# STM32U5A9 register map
File version: 1.0
CPU: CM33 r0p1, little endian, MPU, FPU, 4 interrupt priority bits
Registers are 32-bit, read-write, reset 0x0 unless marked. A register's access mark holds for its fields unless they carry their own. Offsets are from the block's base; [hi:lo] are bit positions; lines under a group give offsets from that group; {n}, {i} and the like mark numbered series; 'fields as' and 'values as' point back to an identical list.

## ADC1
Base 0x42028000
Same registers: ADC2 0x42028100, SEC_ADC1 0x52028000, SEC_ADC2 0x52028100
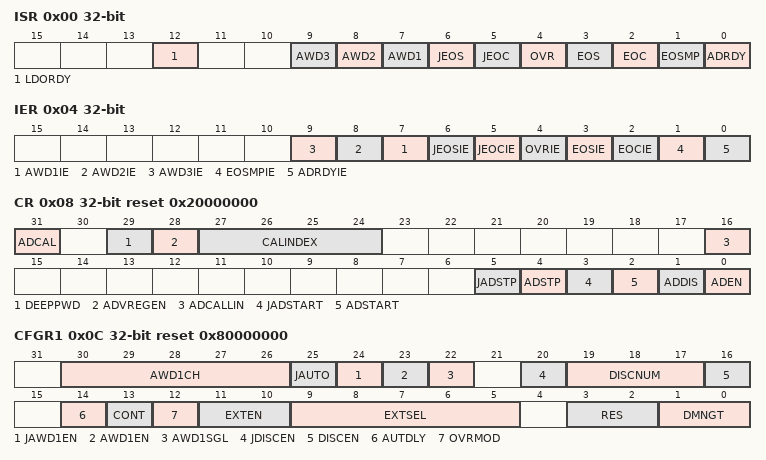
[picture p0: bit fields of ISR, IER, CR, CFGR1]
0x00 ISR access per field — ADC interrupt and status register
  [12] LDORDY ro
    0=Disabled (ADC voltage regulator disabled); 1=Enabled (ADC voltage regulator enabled)
  [n+6] AWD{n} (n=1..3) rw — Analog watchdog {n} flag
    on read: 0=NoEvent (No analog watchdog x event occurred (or the flag event was already acknowledged and cleared by software)); 1=Event (Analog watchdog x event occurred) | on write: 1=Clear the analog watchdog x event flag
  [6] JEOS rw
    on read: 0=NotComplete (Injected conversion sequence not complete (or the flag event was already acknowledged and cleared by software)); 1=Complete (Injected conversions sequence complete) | on write: 1=Clear the injected conversion sequence flag
  [5] JEOC rw
    on read: 0=NotComplete (Injected channel conversion not complete (or the flag event was already acknowledged and cleared by software)); 1=Complete (Injected channel conversion complete) | on write: 1=Clear the injected channel conversion flag
  [4] OVR rw
    on read: 0=No overrun occurred (or the flag event was already acknowledged and cleared by software); 1=Overrun has occurred | on write: 1=Clear the overrun flag
  [3] EOS rw
    on read: 0=NotComplete (Regular conversions sequence not complete (or the flag event was already acknowledged and cleared by software)); 1=Complete (Regular conversions sequence complete) | on write: 1=Clear the regular conversion sequence flag
  [2] EOC rw
    on read: 0=NotComplete (Regular channel conversion not complete (or the flag event was already acknowledged and cleared by software)); 1=Complete (Regular channel conversion complete) | on write: 1=Clear the regular channel conversion flag
  [1] EOSMP rw
    on read: 0=NotAtEnd (Not at the end of the sampling phase (or the flag event was already acknowledged and cleared by software)); 1=AtEnd (End of sampling phase reached) | on write: 1=Clear the sampling phase flag
  [0] ADRDY rw
    on read: 0=NotReady (ADC not yet ready to start conversion (or the flag event was already acknowledged and cleared by software)); 1=Ready (ADC is ready to start conversion) | on write: 1=Clear the ADC ready flag
0x04 IER — ADC interrupt enable register
  [n+6] AWD{n}IE (n=1..3) — Analog watchdog {n} interrupt enable
    0=Disabled (Analog watchdog x interrupt disabled); 1=Enabled (Analog watchdog x interrupt enabled)
  [6] JEOSIE
    0=Disabled (JEOS interrupt disabled); 1=Enabled (JEOS interrupt enabled. An interrupt is generated when the JEOS bit is set.)
  [5] JEOCIE
    0=Disabled (JEOC interrupt disable); 1=Enabled (JEOC interrupt enabled. An interrupt is generated when the JEOC bit is set.)
  [4] OVRIE
    0=Disabled (Overrun interrupt disabled); 1=Enabled (Overrun interrupt enabled. An interrupt is generated when the OVR bit is set.)
  [3] EOSIE
    0=Disabled (EOS interrupt disabled); 1=Enabled (EOS interrupt enabled. An interrupt is generated when the EOS bit is set.)
  [2] EOCIE
    0=Disabled (EOC interrupt disabled); 1=Enabled (EOC interrupt enabled. An interrupt is generated when the EOC bit is set.)
  [1] EOSMPIE
    0=Disabled (EOSMP interrupt disabled); 1=Enabled (EOSMP interrupt enabled. An interrupt is generated when the EOSMP bit is set.)
  [0] ADRDYIE
    0=Disabled (ADRDY interrupt disabled); 1=Enabled (ADRDY interrupt enabled. An interrupt is generated when the ADRDY bit is set.)
0x08 CR reset 0x20000000 — ADC control register
  [31] ADCAL
    on read: 0=NotCalibrating (Calibration complete); 1=Calibrating (Calibration in progress) | on write: 1=StartCalibration (Calibrate the ADC)
  [29] DEEPPWD
    0=Disabled (ADC not in deep-power down); 1=Enabled (ADC in deep-power down)
  [28] ADVREGEN
    values as ISR.LDORDY
  [27:24] CALINDEX
    0=OffsetCalFactor (Offset calibration factor); {v}=CalFactor{v} (Calibration factor {v}) (v=1..6); 7=CalFactor7 (Calibration factor 7 and (write access only) internal offset); 8=Internal offset (read access only); 9=Calibration mode selection
  [16] ADCALLIN
    0=Disabled (Writing ADCAL launches a calibration without the linearity calibration); 1=Enabled (Writing ADCAL launches a calibration with he linearity calibration)
  [5] JADSTP
    on read: 0=NotStopped (No ADC stop injected conversion command ongoing); 1=Stopped (ADSTP command is in progress) | on write: 1=Stop injected conversions ongoing
  [4] ADSTP
    on read: 0=NotStopping (No ADC stop regular conversion command ongoing); 1=Stopping (ADSTP command is in progress) | on write: 1=StopConversion (Stop regular conversions ongoing)
  [3] JADSTART
    on read: 0=NotActive (No ADC injected conversion is ongoing); 1=Active (ADC is operating and eventually converting an injected channel) | on write: 1=Start injected conversions
  [2] ADSTART
    on read: 0=NotActive (No ADC regular conversion is ongoing); 1=Active (ADC is operating and eventually converting a regular channel) | on write: 1=Start regular conversions
  [1] ADDIS
    on read: 0=NotOngoing (No ADDIS command ongoing); 1=InProgress (An ADDIS command is in progress) | on write: 1=Disable the ADC
  [0] ADEN
    on read: 0=Disabled (ADC is disabled); 1=Enabled (ADC is enabled) | on write: 1=Enabled (Enable the ADC)
0x0C CFGR1 reset 0x80000000 — ADC configuration register
  [30:26] AWD1CH range 0..19
  [25] JAUTO
    0=Disabled (Automatic injected group conversion disabled); 1=Enabled (Automatic injected group conversion enabled)
  [24] JAWD1EN
    0=Disabled (Analog watchdog 1 disabled on injected channels); 1=Enabled (Analog watchdog 1 enabled on injected channels)
  [23] AWD1EN
    0=Disabled (Analog watchdog 1 disabled on regular channels); 1=Enabled (Analog watchdog 1 enabled on regular channels)
  [22] AWD1SGL
    0=AllChannels (Analog watchdog 1 enabled on all channels); 1=SingleChannel (Analog watchdog 1 enabled on a single channel)
  [20] JDISCEN
    0=Disabled (Discontinuous mode on injected channels disabled); 1=Enabled (Discontinuous mode on injected channels enabled)
  [19:17] DISCNUM
    0=n1 (1 channel); {v}=n{v+1} ({v+1} channels) (v=1..7)
  [16] DISCEN
    0=Disabled (Discontinuous mode for regular channels disabled); 1=Enabled (Discontinuous mode for regular channels enabled)
  [14] AUTDLY
    0=Disabled (Auto-delayed conversion mode off); 1=Enabled (Auto-delayed conversion mode on)
  [13] CONT
    0=Single conversion mode; 1=Continuous conversion mode
  [12] OVRMOD
    0=Preserve (ADC_DR register is preserved with the old data when an overrun is detected); 1=Overwrite (ADC_DR register is overwritten with the last conversion result when an overrun is detected)
  [11:10] EXTEN
    0=Disabled (Hardware trigger detection disabled (conversions can be launched by software)); 1=RisingEdge (Hardware trigger detection on the rising edge); 2=FallingEdge (Hardware trigger detection on the falling edge); 3=BothEdges (Hardware trigger detection on both the rising and falling edges)
  [9:5] EXTSEL
    0=TIM1_OC1; 1=TIM1_OC2; 2=TIM1_OC3; 3=TIM2_OC2; 4=TIM3_TRGO; 5=TIM4_OC4; 6=EXTI11; 7=TIM8_TRGO; 8=TIM8_TRGO2; 9=TIM1_TRGO; 10=TIM1_TRGO2; 11=TIM2_TRGO; 12=TIM4_TRGO; 13=TIM6_TRGO; 14=TIM15_TRGO; 15=TIM3_OC4; 16=EXTI15; 18=LPTIM1_CH1; 19=LPTIM2_CH1; 20=LPTIM3_CH1; 21=LPTIM4_OUT
  [3:2] RES
    0=FourteenBit (14 bits); 1=TwelveBit (12 bits); 2=TenBit (10 bits); 3=EightBit (8 bits)
  [1:0] DMNGT
    0=DR (Store output data in DR only); 1=DMA One Shot Mode selected; 2=DFSDM (DFSDM mode selected); 3=DMA Circular Mode selected
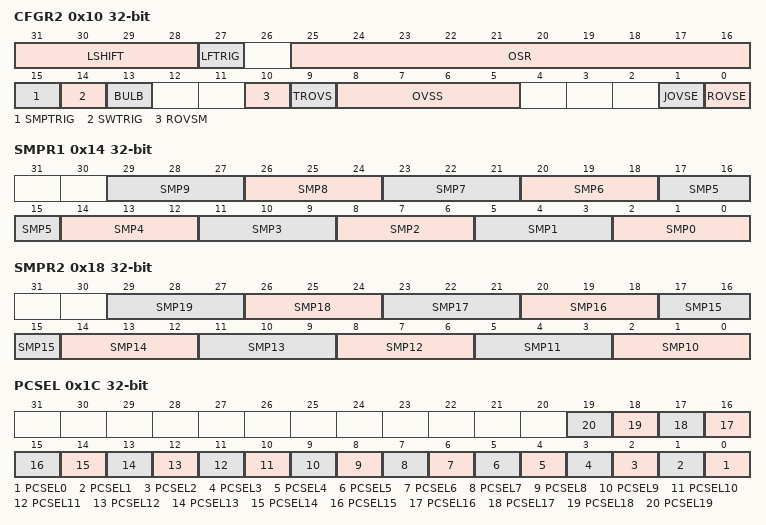
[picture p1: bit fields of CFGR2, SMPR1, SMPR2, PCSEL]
0x10 CFGR2 — ADC configuration register 2
  [31:28] LSHIFT
  [27] LFTRIG
    0=Disabled (Low-frequency trigger mode disabled); 1=Enabled (Low-frequency trigger mode enabled)
  [25:16] OSR
  [15] SMPTRIG
    0=Disabled (Sampling time control trigger mode disabled); 1=Enabled (Sampling time control trigger mode enabled)
  [14] SWTRIG
    0=Disabled (Software trigger starts the conversion for sampling time control trigger mode); 1=Enabled (Software trigger starts the sampling for sampling time control trigger mode)
  [13] BULB
    0=Disabled (Bulb sampling mode disabled); 1=Enabled (Bulb sampling mode enabled. The sampling period starts just after the previous end of the conversion.)
  [10] ROVSM
    0=Continued (When injected conversions are triggered, the oversampling is temporary stopped and continued after the injection sequence (oversampling buffer is maintained during injected sequence)); 1=Resumed (When injected conversions are triggered, the current oversampling is aborted and resumed from start after the injection sequence (oversampling buffer is zeroed by injected sequence start))
  [9] TROVS
    0=Automatic (All oversampled conversions for a channel are done consecutively following a trigger); 1=Triggered (Each oversampled conversion for a channel needs a new trigger)
  [8:5] OVSS range 0..11
  [1] JOVSE
    0=Disabled (Injected oversampling disabled); 1=Enabled (Injected oversampling enabled)
  [0] ROVSE
    0=Disabled (Regular oversampling disabled); 1=Enabled (Regular oversampling enabled)
0x14 SMPR1 — ADC sample time register 1
  [3n+2:3n] SMP{n} (n=0..9) — Channel {n} sample time selection
    0=Cycles5 (5 ADC clock cycles); 1=Cycles6 (6 ADC clock cycles); 2=Cycles12 (12 ADC clock cycles); 3=Cycles20 (20 ADC clock cycles); 4=Cycles36 (36 ADC clock cycles); 5=Cycles68 (68 ADC clock cycles); 6=Cycles391 (391 ADC clock cycles); 7=Cycles814 (814 ADC clock cycles)
0x18 SMPR2 — ADC sample time register 2
  [3n-28:3n-30] SMP{n} (n=10..19) — Channel {n} sample time selection
    values as SMPR1.SMP0
0x1C PCSEL — ADC channel preselection register
  [all] fields
    0=NotPreselected (Input channel x is not preselected for conversion, the ADC conversion of this channel shows a wrong result.); 1=Preselected (Input channel x is preselected for conversion)
  [n] PCSEL{n} (n=0..19)
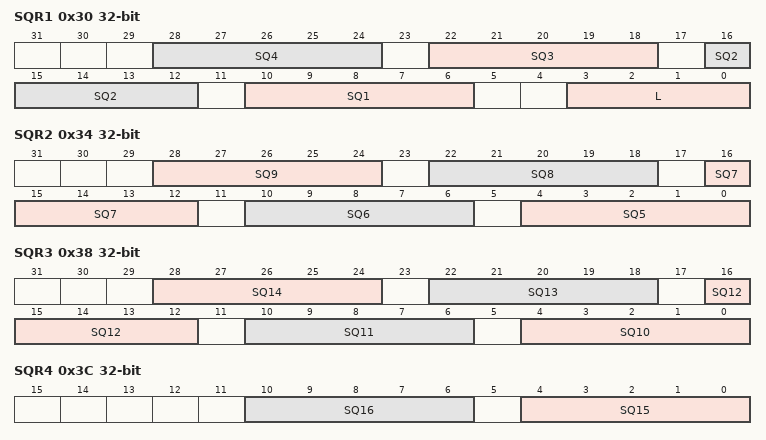
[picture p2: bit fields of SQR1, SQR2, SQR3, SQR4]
0x30 SQR1 — ADC regular sequence register 1
  [6n+4:6n] SQ{n} (n=1..4) — {n} conversion in regular sequence
  [3:0] L
0x34 SQR2 — ADC regular sequence register 2
  [6n-26:6n-30] SQ{n} (n=5..9) — {n} conversion in regular sequence
0x38 SQR3 — ADC regular sequence register 3
  [6n-56:6n-60] SQ{n} (n=10..14) — {n} conversion in regular sequence
0x3C SQR4 — ADC regular sequence register 4
  [6n-86:6n-90] SQ{n} (n=15..16) — {n} conversion in regular sequence
0x40 DR ro — ADC regular Data Register
  [31:0] RDATA
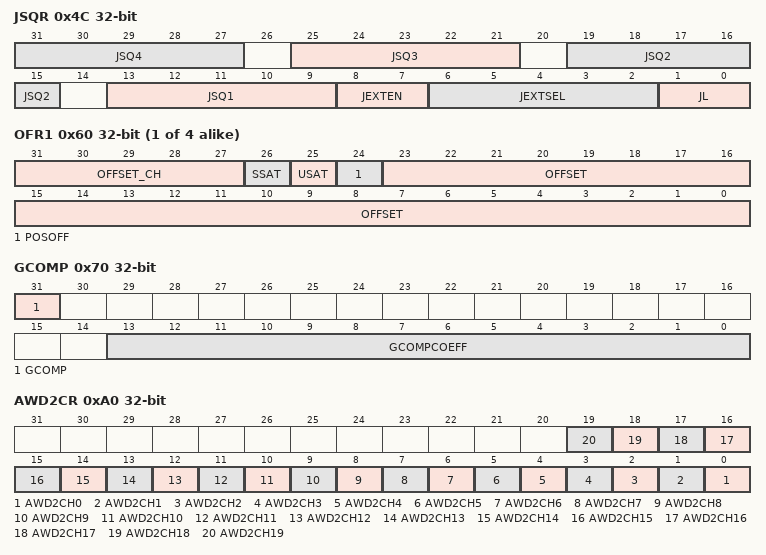
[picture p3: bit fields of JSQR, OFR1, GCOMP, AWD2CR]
0x4C JSQR — ADC injected sequence register
  [6n+7:6n+3] JSQ{n} (n=1..4) — {n} conversion in injected sequence
  [8:7] JEXTEN
    values as CFGR1.EXTEN
  [6:2] JEXTSEL
    0=TIM1_TRGO; 1=TIM1_OC4; 2=TIM2_TRGO; 3=TIM2_OC1; 4=TIM3_OC4; 5=TIM4_TRGO; 6=EXTI15; 7=TIM8_OC4; 8=TIM1_TRGO2; 9=TIM8_TRGO; 10=TIM8_TRGO2; 11=TIM3_OC3; 12=TIM3_TRGO; 13=TIM3_OC1; 14=TIM6_TRGO; 15=TIM15_TRGO; 16=LPTIM1_CH2; 17=LPTIM2_CH2; 18=LPTIM3_CH1; 19=LPTIM4_OUT1
  [1:0] JL
{0x5C+4i} OFR{i} (i=1..4) — ADC offset register
  [31:27] OFFSET_CH
  [26] SSAT
    0=Disabled (Offset is subtracted maintaining data integrity and extending converted data size (9-bit and 15-bit signed format)); 1=Enabled (Offset is subtracted and result is saturated to maintain converted data size)
  [25] USAT
    0=Disabled (Offset is subtracted maintaining data integrity and keeping converted data size); 1=Enabled (Offset is subtracted and result is saturated to maintain converted data size)
  [24] POSOFF
    0=Negative offset; 1=Positive offset
  [23:0] OFFSET
0x70 GCOMP — ADC gain compensation register
  [31] GCOMP
    0=Disabled (Regular ADC operating mode); 1=Enabled (Gain compensation enabled and applied to all channels)
  [13:0] GCOMPCOEFF
{0x7C+4i} JDR{i} (i=1..4) ro — ADC injected data register
  [31:0] JDATA
0xA0 AWD2CR — ADC analog watchdog 2 configuration register
  [n] AWD2CH{n} (n=0..19)
    0=Disabled (ADC analog input channel x is not monitored by AWDy); 1=Enabled (ADC analog input channel x is monitored by AWDy)
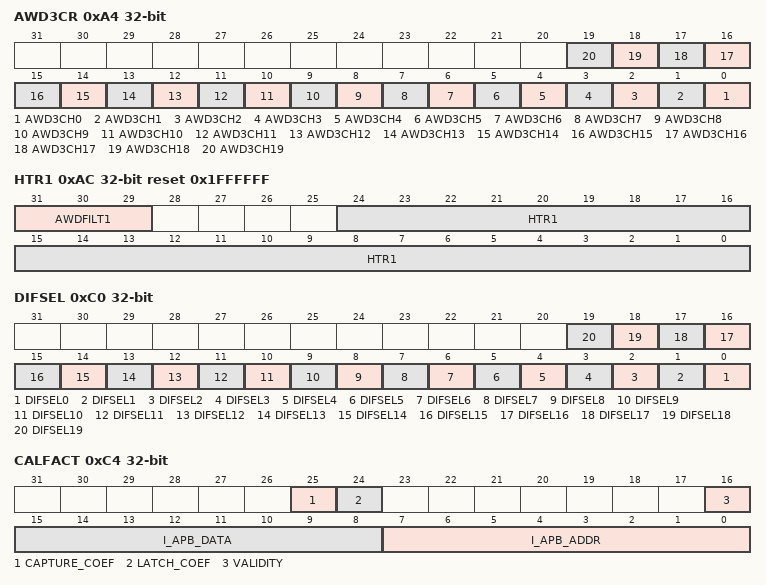
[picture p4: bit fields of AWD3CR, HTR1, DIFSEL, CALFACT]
0xA4 AWD3CR — ADC analog watchdog 3 configuration register
  [n] AWD3CH{n} (n=0..19)
    values as AWD2CR.AWD2CH0
0xA8 LTR1 — ADC watchdog threshold register 1
  [24:0] LTR1
0xAC HTR1 reset 0x1FFFFFF — ADC watchdog threshold register 1
  [31:29] AWDFILT1
    0=NoFiltering; 1=Detections2 (Two consecutive detections generates an AWDx flag or an interrupt); 2=Detections3 (Three consecutive detections generates an AWDx flag or an interrupt); 3=Detections4 (Four consecutive detections generates an AWDx flag or an interrupt); 4=Detections5 (Five consecutive detections generates an AWDx flag or an interrupt); 5=Detections6 (Six consecutive detections generates an AWDx flag or an interrupt); 6=Detections7 (Seven consecutive detections generates an AWDx flag or an interrupt); 7=Detections8 (Eight consecutive detections generates an AWDx flag or an interrupt)
  [24:0] HTR1
0xB0 LTR2 — ADC watchdog lower threshold register 2
  [24:0] LTR2
0xB4 HTR2 reset 0x1FFFFFF — ADC watchdog higher threshold register 2
  [24:0] HTR2
0xB8 LTR3 — ADC watchdog lower threshold register 3
  [24:0] LTR3
0xBC HTR3 reset 0x1FFFFFF — ADC watchdog higher threshold register 3
  [24:0] HTR3
0xC0 DIFSEL — ADC differential mode selection register
  [n] DIFSEL{n} (n=0..19) — Differential mode for channel {n}
    0=SingleEnded (ADC analog input channel x is configured in single-ended mode); 1=Differential (ADC analog input channel x is configured in differential mode)
0xC4 CALFACT access per field — ADC user control register
  [25] CAPTURE_COEF rw
    0=Disabled (Calibration factor not captured); 1=Enabled (Calibration factor available in CALFACT[31:0] bits, the calibration factor index being defined by CALINDEX[3:0] bits)
  [24] LATCH_COEF rw
    0=NoEffect; 1=Latch (Calibration factor latched in the analog block on LATCH_COEF bit transition from 0 to 1. Prior to latching the calibration factor, CALFACT[31:0] bits must be programmed with the content of CALINDEX[3:0] bits.)
  [16] VALIDITY ro
    0=InProgress (Operation still in progress); 1=Complete (Operation complete)
  [15:8] I_APB_DATA ro
  [7:0] I_APB_ADDR ro
0xC8 CALFACT2 — ADC calibration factor register
  [31:0] CALFACT
